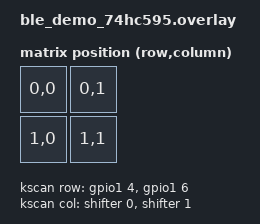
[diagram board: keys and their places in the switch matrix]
// This file was generated from a template. Edit it to match your keyboard.
// See https://zmk.dev/docs/development/hardware-integration/new-shield for more
// instructions.

#include <dt-bindings/zmk/matrix_transform.h>
#include <dt-bindings/led/led.h>
#include "ble_demo_74hc595-layouts.dtsi"

/ {
    chosen {
        zmk,physical-layout = &default_layout;
        zmk,underglow = &led_strip;
    };


    

    kscan: kscan {
        // If the hardware does not use a switch matrix, change this to the
        // appropriate driver and update the properties below to match.
        // See https://zmk.dev/docs/config/kscan for supported key scan drivers.
        compatible = "zmk,kscan-gpio-matrix";
        // Set this to "col2row" or "row2col" to match the hardware. If using
        // "row2col", change the col-gpios to (GPIO_ACTIVE_HIGH | GPIO_PULL_DOWN)
        // and the row-gpios to GPIO_ACTIVE_HIGH.
        diode-direction = "col2row";
        wakeup-source;

        // Replace these comments with the GPIO pins in the matrix.
        // See https://zmk.dev/docs/development/hardware-integration/new-shield#shield-overlays
        col-gpios
            = <&shifter 0 GPIO_ACTIVE_HIGH>
            , <&shifter 1 GPIO_ACTIVE_HIGH>
            ;

        row-gpios
            = <&gpio1 4 (GPIO_ACTIVE_HIGH | GPIO_PULL_DOWN)>
            , <&gpio1 6 (GPIO_ACTIVE_HIGH | GPIO_PULL_DOWN)>
            ;
    };

    default_transform: default_transform {
        // See https://zmk.dev/docs/development/hardware-integration/new-shield#matrix-transform
        // for how to configure this
        compatible = "zmk,matrix-transform";
        columns = <2>;
        rows = <2>;

        map = <
            RC(0, 0) RC(0, 1)
            RC(1, 0) RC(1, 1)
        >;
    };
    
};


// led 支持 https://zmk.dev/docs/development/hardware-integration/lighting/underglow#nrf52-based-boards
&pinctrl {

    // rgb led
    spi3_default: spi3_default {
        group1 {
            psels = <NRF_PSEL(SPIM_MOSI, 0, 24)>;
        };
    };

    spi3_sleep: spi3_sleep {
        group1 {
            psels = <NRF_PSEL(SPIM_MOSI, 0, 24)>;
            low-power-enable;
        };
    };

    //74hc595 支持
 spi0_default: spi0_default {
        group1 {
            psels = <NRF_PSEL(SPIM_SCK, 0, 17)>,
                    <NRF_PSEL(SPIM_MOSI, 0, 20)>;
        };
    };
    spi0_sleep: spi0_sleep {
        group1 {
            psels = <NRF_PSEL(SPIM_SCK, 0, 17)>,
                    <NRF_PSEL(SPIM_MOSI, 0, 20)>;
            low-power-enable;
        };
    };

};

&spi3 {
    compatible = "nordic,nrf-spim";
    status = "okay";

    pinctrl-0 = <&spi3_default>;
    pinctrl-1 = <&spi3_sleep>;
    pinctrl-names = "default", "sleep";

    led_strip: ws2812@0 {
        compatible = "worldsemi,ws2812-spi";

        /* SPI */
        reg = <0>; /* ignored, but necessary for SPI bindings */
        spi-max-frequency = <4000000>;

        /* WS2812 */
        chain-length = <10>; /* number of LEDs */
        spi-one-frame = <0x70>;
        spi-zero-frame = <0x40>;
        color-mapping = <LED_COLOR_ID_GREEN
                         LED_COLOR_ID_RED
                         LED_COLOR_ID_BLUE>;
    };
};


// 74hc595 支持
&spi0 {
    compatible = "nordic,nrf-spim";
    status = "okay";
    pinctrl-0 = <&spi0_default>;
    pinctrl-1 = <&spi0_sleep>;
    pinctrl-names = "default", "sleep";

    // 74hc595 时钟引脚
    cs-gpios = <&gpio0 22 GPIO_ACTIVE_LOW>

    shifter: 595@0 {
        compatible = "zmk,gpio-595";
        status = "okay";
        gpio-controller;
        spi-max-frequency = <200000>;
        reg = <0>; /* 对应上面 cs-gpios 的索引 0 */
        #gpio-cells = <2>;
        ngpios = <8>;  //595级联数量*8
    };
};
